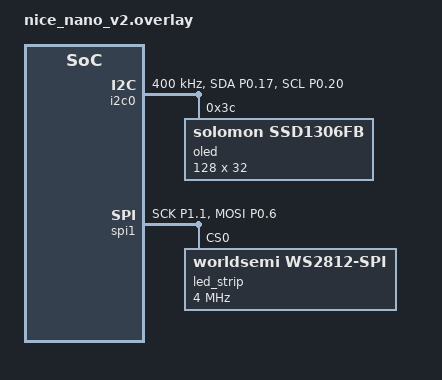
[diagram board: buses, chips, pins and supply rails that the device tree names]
/**
 * Generated by Shield Wizard for ZMK
 * Applies to part "left" with controller "nice_nano_v2"
 */

// pin control for i2c0
// - SDA on D2
// - SCL on D3
&pinctrl {
    /* configuration for i2c0 device, default state */
    i2c0_default: i2c0_default {
        group1 {
            psels = <NRF_PSEL(TWIM_SDA, 0, 17)>,
                    <NRF_PSEL(TWIM_SCL, 0, 20)>;
        };
    };
    /* configuration for i2c0 device, sleep state */
    i2c0_sleep: i2c0_sleep {
        group1 {
            psels = <NRF_PSEL(TWIM_SDA, 0, 17)>,
                    <NRF_PSEL(TWIM_SCL, 0, 20)>;
            low-power-enable;
        };
    };
};
&i2c0 {
    //compatible = "nordic,nrf-twim";
    status = "okay";
    pinctrl-0 = <&i2c0_default>;
    pinctrl-1 = <&i2c0_sleep>;
    pinctrl-names = "default", "sleep";
    clock-frequency = <I2C_BITRATE_FAST>;//把 I2C 从 400kHz 降到 100kHz
     //clock-frequency = <I2C_BITRATE_STANDARD>;
};

// devices on i2c0

&i2c0 {
    oled: ssd1306@3c {
        compatible = "solomon,ssd1306fb";
        reg = <0x3c>;
        width = <128>;
        height = <32>;

        segment-offset = <0>;
        page-offset = <0>;
        display-offset = <0>;
        multiplex-ratio = <31>;
        prechargep = <0x22>;
        //segment-remap;
        //com-invdir;
        com-sequential;
        inversion-on;
    };
};
/ {
    chosen {
        zephyr,display = &oled;
    };
};

// pin control for spi1
// - SCK on P1.01
// - MOSI on D1
&pinctrl {
    /* configuration for spi1 device, default state */
    spi1_default: spi1_default {
        group1 {
            psels = <NRF_PSEL(SPIM_SCK, 1, 1)>,
                    <NRF_PSEL(SPIM_MOSI, 0, 6)>;
        };
    };
    /* configuration for spi1 device, sleep state */
    spi1_sleep: spi1_sleep {
        group1 {
            psels = <NRF_PSEL(SPIM_SCK, 1, 1)>,
                    <NRF_PSEL(SPIM_MOSI, 0, 6)>;
            low-power-enable;
        };
    };
};
&spi1 {
    compatible = "nordic,nrf-spim";
    status = "okay";
    pinctrl-0 = <&spi1_default>;
    pinctrl-1 = <&spi1_sleep>;
    pinctrl-names = "default", "sleep";
};

// devices on spi1

#include <dt-bindings/led/led.h>
&spi1 {
    led_strip: ws2812@0 {
        compatible = "worldsemi,ws2812-spi";
        reg = <0>;
        spi-max-frequency = <4000000>;

        chain-length = <8>;
        spi-one-frame = <0x70>;
        spi-zero-frame = <0x40>;
        color-mapping = <LED_COLOR_ID_GREEN
                         LED_COLOR_ID_RED
                         LED_COLOR_ID_BLUE>;
    };
};
/ {
    chosen {
        zmk,underglow = &led_strip;
    };
};
// ===== 高密度OLED布局配置（完整版） =====
/ {
    // 先定义显示组件的样式和字体
    display_group {
        compatible = "zmk,display-group";
        display = <&oled>;
        
        // 使用小字体以显示更多内容
        font = <&lv_font_montserrat_8>;  // 8像素字体，比默认小
    };
    
    // 定义各个Widget
    widgets {
        compatible = "zmk,display-widgets";
        
        // 【第1行】层状态 + 电池
        layer_status: layer_status {
            compatible = "zmk,display-widget-layer";
            x = <0>;
            y = <0>;
            width = <3>;    // 显示 "L0"
            height = <1>;
        };
        
        battery_status: battery_status {
            compatible = "zmk,display-widget-battery";
            x = <5>;        // 向右移，避免重叠
            y = <0>;
            width = <6>;    // 显示 "BAT 85%"
            height = <1>;
        };
        
        // 【第2行】输出状态 + WPM
        output_status: output_status {
            compatible = "zmk,display-widget-output";
            x = <0>;
            y = <1>;
            width = <4>;    // 显示 "USB" 或 "BLE"
            height = <1>;
        };
        
        wpm_status: wpm_status {
            compatible = "zmk,display-widget-wpm";
            x = <5>;
            y = <1>;
            width = <6>;    // 显示 "WPM 45"
            height = <1>;
        };
        
        // 【第3行】编码器
        encoder_status: encoder_status {
            compatible = "zmk,display-widget-encoder";
            x = <0>;
            y = <2>;
            width = <8>;    // 显示 "VOL 32"
            height = <1>;
        };
        
        // 【第4行】连接状态（全屏宽）
        connection_status: connection_status {
            compatible = "zmk,display-widget-connection";
            x = <0>;
            y = <3>;
            width = <14>;   // 显示设备名
            height = <1>;
        };
    };
};

// 将Widget列表关联到OLED
&oled {
    status = "okay";
    // 注意：这里需要引用widgets节点的路径
    widgets = <&layer_status &battery_status &output_status 
               &wpm_status &encoder_status &connection_status>;
};
